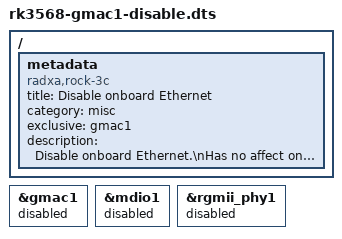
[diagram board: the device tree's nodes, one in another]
/dts-v1/;
/plugin/;

/ {
	metadata {
		title = "Disable onboard Ethernet";
		compatible = "radxa,rock-3c";
		category = "misc";
		exclusive = "gmac1";
		description = "Disable onboard Ethernet.\nHas no affect on external Ethernet (for example USB adapter).";
	};

	fragment@0 {
		target = <&gmac1>;

		__overlay__ {
			status = "disabled";
		};
	};

	fragment@1 {
		target = <&mdio1>;

		__overlay__ {
			status = "disabled";
		};
	};

	fragment@2 {
		target = <&rgmii_phy1>;

		__overlay__ {
			status = "disabled";
		};
	};
};
